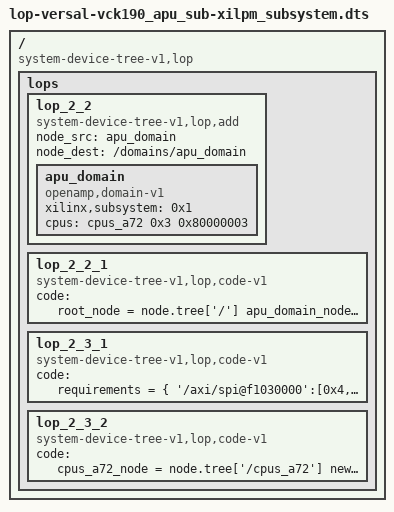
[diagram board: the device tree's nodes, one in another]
/dts-v1/;
/ {
	compatible = "system-device-tree-v1,lop";
	lops {

		lop_2_2 {
			compatible = "system-device-tree-v1,lop,add";
			node_src = "apu_domain";
			node_dest = "/domains/apu_domain";
			apu_domain {
				compatible = "openamp,domain-v1";
				xilinx,subsystem = <0x1>;
				#xilinx,config-cells = <2>;
				
				/* cdo add subsystem for apu is inferred as cpus_a72 is in cpu field */
				cpus = <&cpus_a72 0x3 0x80000003>;
			};
		};

		lop_2_2_1 {
			compatible = "system-device-tree-v1,lop,code-v1";
			code = "
			root_node = node.tree['/']
			apu_domain_node = node.tree['/domains/apu_domain']
			new_phandle = root_node.tree.phandle_gen()
			newprop = LopperProp(name='phandle',value=new_phandle)
			apu_domain_node.phandle = new_phandle
			apu_domain_node + newprop
			apu_domain_node.sync( root_node.tree.fdt )
			";
		};


		lop_2_3_1 {
			compatible = "system-device-tree-v1,lop,code-v1";
			code = "
			requirements = {

			'/axi/spi@f1030000':[0x4,0xfffff],
			'/amba_pl/ai_engine@40000000':[0x4,0xfffff],
			'/axi/serial@ff000000':[0x5,0x38],
			'/axi/serial@ff010000':[0x7,0x38],
			'/axi/mailbox@ff330000':[0x8104,0xfffff],
			'/axi/mailbox@ff340000':[0x4,0xfffff],
			'/axi/mailbox@ff350000':[0x4,0xfffff],
			'/axi/mailbox@ff360000':[0x4,0xfffff],
			'/axi/mailbox@ff370000':[0x4,0xfffff],
			'/axi/mailbox@ff380000':[0x4,0xfffff],
			'/axi/mailbox@ff3a0000':[0x4,0xfffff],
			'/memory@fffc0000':[0x8304,0xfffff],
			'/axi/psv_tcm_global@ffe00000':[0x4,0xfffff],
			'/axi/psv_tcm_global@ffe20000':[0x4,0xfffff],
			'/axi/psv_tcm_global@ffe90000':[0x4,0xfffff],
			'/axi/psv_tcm_global@ffeb0000':[0x4,0xfffff],

			'/cpus_a72/cpu@0':[0x8104,0xfffff],
			'/cpus_a72/cpu@1':[0x8104,0xfffff],

			'/axi/ethernet@ff0c0000':[0x8706,0x38],
			'/axi/ethernet@ff0d0000':[0x8706,0x38],
			'/axi/sdhci@f1040000':[0x7,0x38],
			'/axi/sdhci@f1050000':[0x7,0xfffff],

			'/axi/can@ff060000':[0x4,0xfffff],
			'/axi/can@ff070000':[0x4,0xfffff],
			'/axi/i2c@ff020000':[0x4,0xfffff],
			'/axi/i2c@ff030000':[0x4,0xfffff],
			'/axi/dma@ffaf0000':[0x4,0xfffff],
			'/axi/dma@ffae0000':[0x4,0xfffff],
			'/axi/dma@ffad0000':[0x4,0xfffff],
			'/axi/dma@ffac0000':[0x4,0xfffff],
			'/axi/dma@ffab0000':[0x4,0xfffff],
			'/axi/dma@ffaa0000':[0x4,0xfffff],
			'/axi/dma@ffa90000':[0x4,0xfffff],
			'/axi/dma@ffa80000':[0x4,0xfffff],
			'/memory@800000000':[0x7,0x38],
			'/axi/rtc@f12a0000':[0x4,0xfffff],
			'/axi/timer@ff0e0000':[0x4,0xfffff],
			'/axi/usb@ff9d0000':[0x7,0x38],
			'/axi/watchdog@fd4d0000':[0x7,0x38],
			'/axi/gpio@ff0b0000':[0x4,0xfffff],
			'/axi/gpio@f1020000':[0x4,0xfffff],
			'/axi/spi@ff040000':[0x4,0xfffff],
			'/axi/spi@ff050000':[0x4,0xfffff],
			}

			device_list = []

			# set device list for apu domain
			apu_domain_node = node.tree['/domains/apu_domain']
		
			# for each device in nodes_to_update:
			# find node in tree with name
			# generate phandle for that node
			# add to prop the following: 'phandle nodes_to_update[info]'
			for n in requirements.keys():
				target_node = apu_domain_node.tree[n]
				device_list.append(target_node.propval('phandle'))
				device_list.append(requirements[n][0])
				device_list.append(requirements[n][1])

			device_list_prop = LopperProp(name='xilinx,subsystem-config',value=device_list)

			apu_domain_node + device_list_prop
			apu_domain_node.sync( apu_domain_node.tree.fdt )
			";
		};

		lop_2_3_2 {
			compatible = "system-device-tree-v1,lop,code-v1";
			code = "
			cpus_a72_node = node.tree['/cpus_a72']
			new_phandle = cpus_a72_node.tree.phandle_gen()
			newprop = LopperProp(name='phandle',value=new_phandle)
			cpus_a72_node.phandle = new_phandle
			cpus_a72_node + newprop
			cpus_a72_node.sync( cpus_a72_node.tree.fdt )

			# set cpus to reference the new phandle
			apu_domain_node = node.tree['/domains/apu_domain']
			apu_domain_node_cpus = apu_domain_node.propval('cpus')
			apu_domain_node_cpus[0] = new_phandle
			apu_domain_node['cpus'].value = apu_domain_node_cpus
			";
                };
	};

};
